# nrf7120E_enga_application register map
Vendor: Nordic Semiconductor; Series: nrf71; File version: 1
CPU: CM33 r0p4, little endian, MPU, FPU, 3 interrupt priority bits, 270 interrupts, 4 SAU regions
Registers are 32-bit, read-write, reset 0x0 unless marked. A register's access mark holds for its fields unless they carry their own. Offsets are from the block's base; [hi:lo] are bit positions; lines under a group give offsets from that group; {n}, {i} and the like mark numbered series; 'fields as' and 'values as' point back to an identical list.

## GLOBAL_TAMPC_S — Tamper controller
Base 0x500EF000
0x100 EVENTS_TAMPER — Tamper controller detected an error.
  [0] EVENTS_TAMPER
    0=NotGenerated (Event not generated); 1=Generated (Event generated)
0x104 EVENTS_WRITEERROR — Attempt to write a VALUE in PROTECT registers without clearing the WRITEPROTECT.
  [0] EVENTS_WRITEERROR
    values as EVENTS_TAMPER.EVENTS_TAMPER
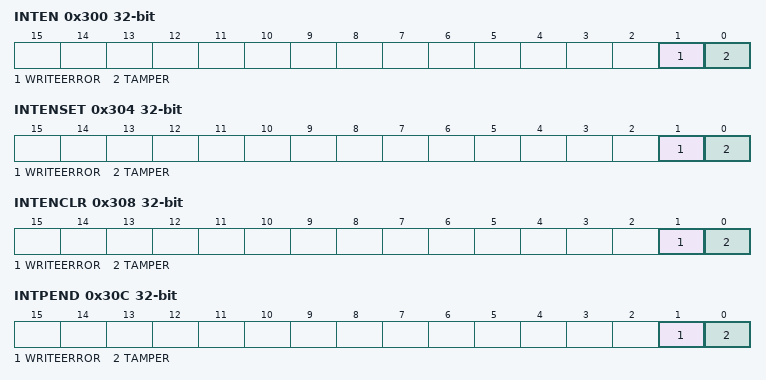
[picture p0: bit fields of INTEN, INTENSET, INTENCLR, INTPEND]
0x300 INTEN — Enable or disable interrupt
  [1] WRITEERROR — Enable or disable interrupt for event WRITEERROR
    0=Disabled; 1=Enabled
  [0] TAMPER — Enable or disable interrupt for event TAMPER
    0=Disabled; 1=Enabled
0x304 INTENSET — Enable interrupt
  [1] WRITEERROR write-1-sets — Write '1' to enable interrupt for event WRITEERROR
    on read: 0=Disabled (Read: Disabled); 1=Enabled (Read: Enabled) | on write: 1=Set (Enable)
  [0] TAMPER write-1-sets — Write '1' to enable interrupt for event TAMPER
    values as WRITEERROR
0x308 INTENCLR — Disable interrupt
  [1] WRITEERROR write-1-clears — Write '1' to disable interrupt for event WRITEERROR
    on read: 0=Disabled (Read: Disabled); 1=Enabled (Read: Enabled) | on write: 1=Clear (Disable)
  [0] TAMPER write-1-clears — Write '1' to disable interrupt for event TAMPER
    values as WRITEERROR
0x30C INTPEND ro — Pending interrupts
  [1] WRITEERROR — Read pending status of interrupt for event WRITEERROR
    on read: 0=NotPending (Read: Not pending); 1=Pending (Read: Pending)
  [0] TAMPER — Read pending status of interrupt for event TAMPER
    values as WRITEERROR
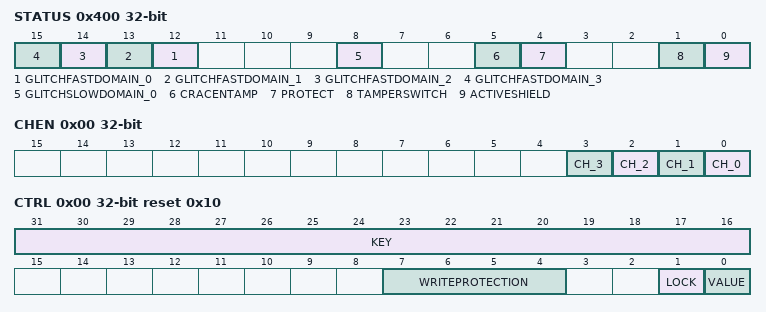
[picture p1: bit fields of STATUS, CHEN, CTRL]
0x400 STATUS write-1-clears — The tamper controller status.
  [all] fields
    0=NotDetected; 1=Detected
  [n+12] GLITCHFASTDOMAIN_{n} (n=0..3) — Fast domain glitch detector {n} detected an error.
  [8] GLITCHSLOWDOMAIN_0 — Slow domain glitch detector 0 detected an error.
  [5] CRACENTAMP — CRACEN detected an error.
  [4] PROTECT — Error detected for the protected signals.
  [1] TAMPERSWITCH — External tamper switch detector detected an error.
  [0] ACTIVESHIELD — Active shield detector detected an error.
0x404 ACTIVESHIELD group — Unspecified
  0x00 CHEN — Active shield detector channel enable register.
    [all] fields
      0=Disabled (Disable channel.); 1=Enabled (Enable channel.)
    [n] CH_{n} (n=0..3) — Enable or disable active shield channel {n}.
0x500 PROTECT group — Unspecified
  {0x0+0x20*j} DOMAIN[{j}] (j=0..0) group — Unspecified
    0x00 DBGEN group — Unspecified
      0x00 CTRL reset 0x10 — Description cluster: Control register for invasive (halting) debug enable for the local debug components within domain n.
        [31:16] KEY wo — Required write key for upper 16 bits. Must be included in all register write operations.
          0x50FA=KEY (Write key value.)
        [7:4] WRITEPROTECTION — The write protection must be cleared to allow updates to the VALUE field.
          0=Disabled (Read: Write protection is disabled.); 1=Enabled (Read: Write protection is enabled.); 15=Clear (Write: Value to clear write protection.)
        [1] LOCK write-once write-1-sets — Lock this register to prevent changes to the VALUE field until next reset.
          0=Disabled (Lock disabled.); 1=Enabled (Lock enabled.)
        [0] VALUE — Set value of dbgen signal.
          0=Low (Signal is logic 0, indicating that invasive debug is disabled.); 1=High (Signal is logic 1, indicating that invasive debug is enabled.)
      0x04 STATUS write-1-clears — Description cluster: Status register for invasive (halting) debug enable for domain n.
        [0] ERROR — Error detection status.
          0=No error detected; 1=Error detected
    0x08 NIDEN group — Unspecified
      0x00 CTRL reset 0x10 — Description cluster: Control register for non-invasive debug enable for the local debug components within domain n.
        [31:16] KEY wo — Required write key for upper 16 bits. Must be included in all register write operations.
          0x50FA=KEY (Write key value.)
        [7:4] WRITEPROTECTION — The write protection must be cleared to allow updates to the VALUE field.
          values as PROTECT.DOMAIN[0].DBGEN.CTRL.WRITEPROTECTION
        [1] LOCK write-once write-1-sets — Lock this register to prevent changes to the VALUE field until next reset.
          0=Disabled (Lock disabled.); 1=Enabled (Lock enabled.)
        [0] VALUE — Set value of niden signal.
          0=Low (Signal is logic 0, indicating that non-invasive debug is disabled.); 1=High (Signal is logic 1, indicating that non-invasive debug is enabled.)
      0x04 STATUS write-1-clears — Description cluster: Status register for non-invasive debug enable for domain n.
        fields as PROTECT.DOMAIN[0].DBGEN.STATUS
    0x10 SPIDEN group — Unspecified
      0x00 CTRL reset 0x10 — Description cluster: Control register for secure priviliged invasive (halting) debug enable for the local debug components within domain n.
        [31:16] KEY wo — Required write key for upper 16 bits. Must be included in all register write operations.
          0x50FA=KEY (Write key value.)
        [7:4] WRITEPROTECTION — The write protection must be cleared to allow updates to the VALUE field.
          values as PROTECT.DOMAIN[0].DBGEN.CTRL.WRITEPROTECTION
        [1] LOCK write-once write-1-sets — Lock this register to prevent changes to the VALUE field until next reset.
          0=Disabled (Lock disabled.); 1=Enabled (Lock enabled.)
        [0] VALUE — Set value of spiden signal.
          0=Low (Signal is logic 0, indicating that secure priviliged invasive debug is disabled.); 1=High (Signal is logic 1, indicating that secure priviliged invasive debug is enabled.)
      0x04 STATUS write-1-clears — Description cluster: Status register for secure priviliged invasive (halting) debug enable for domain n.
        fields as PROTECT.DOMAIN[0].DBGEN.STATUS
    0x18 SPNIDEN group — Unspecified
      0x00 CTRL reset 0x10 — Description cluster: Control register for secure priviliged non-invasive debug enable for the local debug components within domain n.
        [31:16] KEY wo — Required write key for upper 16 bits. Must be included in all register write operations.
          0x50FA=KEY (Write key value.)
        [7:4] WRITEPROTECTION — The write protection must be cleared to allow updates to the VALUE field.
          values as PROTECT.DOMAIN[0].DBGEN.CTRL.WRITEPROTECTION
        [1] LOCK write-once write-1-sets — Lock this register to prevent changes to the VALUE field until next reset.
          0=Disabled (Lock disabled.); 1=Enabled (Lock enabled.)
        [0] VALUE — Set value of spniden signal.
          0=Low (Signal is logic 0, indicating that secure priviliged non-invasive debug is disabled.); 1=High (Signal is logic 1, indicating that secure priviliged non-invasive debug is enabled.)
      0x04 STATUS write-1-clears — Description cluster: Status register for secure priviliged non-invasive debug enable for domain n.
        fields as PROTECT.DOMAIN[0].DBGEN.STATUS
  {0x200+0x10*j} AP[{j}] (j=0..0) group — Unspecified
    0x00 DBGEN group — Unspecified
      0x00 CTRL reset 0x10 — Description cluster: Control register to enable invasive (halting) debug in domain ns access port.
        fields as PROTECT.DOMAIN[0].DBGEN.CTRL
      0x04 STATUS write-1-clears — Description cluster: Status register for invasive (halting) debug enable for domain ns access port.
        fields as PROTECT.DOMAIN[0].DBGEN.STATUS
  0x370 RESETBEHAVIOR group — Unspecified
    0x00 CTRL reset 0x10 — Control register allows for the configuration of reset behavior for specific signals.
      [31:16] KEY wo — Required write key for upper 16 bits. Must be included in all register write operations.
        0x50FA=KEY (Write key value.)
      [7:4] WRITEPROTECTION — The write protection must be cleared to allow updates to the VALUE field.
        values as PROTECT.DOMAIN[0].DBGEN.CTRL.WRITEPROTECTION
      [1] LOCK write-once write-1-sets — Lock this register to prevent changes to the VALUE field until next reset.
        0=Disabled (Lock disabled.); 1=Enabled (Lock enabled.)
      [0] VALUE — Determines the reset behavior for specific signals under certain conditions as defined by the device implementation.
        0=Low (No reset action is triggered for the specified conditions.); 1=High (A reset action is initiated for the specified conditions, resetting the targeted signals to their default state.)
    0x04 STATUS write-1-clears — Status register for the reset control register.
      fields as PROTECT.DOMAIN[0].DBGEN.STATUS
  0x400 ACTIVESHIELD group — Enable active shield detector.
    0x00 CTRL reset 0x10 — Control register for active shield detector enable signal.
      [31:16] KEY wo — Required write key for upper 16 bits. Must be included in all register write operations.
        0x50FA=KEY (Write key value.)
      [7:4] WRITEPROTECTION — The write protection must be cleared to allow updates to the VALUE field.
        values as PROTECT.DOMAIN[0].DBGEN.CTRL.WRITEPROTECTION
      [1] LOCK write-once write-1-sets — Lock this register to prevent changes to the VALUE field until next reset.
        0=Disabled (Lock disabled.); 1=Enabled (Lock enabled.)
      [0] VALUE — Set value of active shield enable signal.
        0=Low (Signal is logic 0.); 1=High (Signal is logic 1.)
    0x04 STATUS write-1-clears — Status register for active shield detector enable signal.
      fields as PROTECT.DOMAIN[0].DBGEN.STATUS
  0x408 TAMPERSWITCH group — Enable tamper switch detector.
    0x00 CTRL reset 0x10 — Control register for external tamper switch enable signal.
      [31:16] KEY wo — Required write key for upper 16 bits. Must be included in all register write operations.
        0x50FA=KEY (Write key value.)
      [7:4] WRITEPROTECTION — The write protection must be cleared to allow updates to the VALUE field.
        values as PROTECT.DOMAIN[0].DBGEN.CTRL.WRITEPROTECTION
      [1] LOCK write-once write-1-sets — Lock this register to prevent changes to the VALUE field until next reset.
        0=Disabled (Lock disabled.); 1=Enabled (Lock enabled.)
      [0] VALUE — Set value of tamper switch enable signal.
        0=Low (Signal is logic 0.); 1=High (Signal is logic 1.)
    0x04 STATUS write-1-clears — Status register for external tamper switch detector enable signal.
      fields as PROTECT.DOMAIN[0].DBGEN.STATUS
  0x438 CRACENTAMP group — Enable tamper detector from CRACEN.
    0x00 CTRL reset 0x11 — Control register for CRACEN tamper detector enable signal.
      [31:16] KEY wo — Required write key for upper 16 bits. Must be included in all register write operations.
        0x50FA=KEY (Write key value.)
      [7:4] WRITEPROTECTION — The write protection must be cleared to allow updates to the VALUE field.
        values as PROTECT.DOMAIN[0].DBGEN.CTRL.WRITEPROTECTION
      [1] LOCK write-once write-1-sets — Lock this register to prevent changes to the VALUE field until next reset.
        0=Disabled (Lock disabled.); 1=Enabled (Lock enabled.)
      [0] VALUE — Set value of CRACEN tamper detector enable signal.
        0=Low (Signal is logic 0.); 1=High (Signal is logic 1.)
    0x04 STATUS write-1-clears — Status register for CRACEN tamper detector enable signal.
      fields as PROTECT.DOMAIN[0].DBGEN.STATUS
  0x440 GLITCHSLOWDOMAIN group — Enable slow domain glitch detectors.
    0x00 CTRL reset 0x11 — Control register for slow domain glitch detectors enable signal.
      [31:16] KEY wo — Required write key for upper 16 bits. Must be included in all register write operations.
        0x50FA=KEY (Write key value.)
      [7:4] WRITEPROTECTION — The write protection must be cleared to allow updates to the VALUE field.
        values as PROTECT.DOMAIN[0].DBGEN.CTRL.WRITEPROTECTION
      [1] LOCK write-once write-1-sets — Lock this register to prevent changes to the VALUE field until next reset.
        0=Disabled (Lock disabled.); 1=Enabled (Lock enabled.)
      [0] VALUE — Set value of slow domain glitch detectors enable signal.
        0=Low (Signal is logic 0.); 1=High (Signal is logic 1.)
    0x04 STATUS write-1-clears — Status register for slow domain glitch detectors enable signal.
      fields as PROTECT.DOMAIN[0].DBGEN.STATUS
  0x448 GLITCHFASTDOMAIN group — Enable fast domain glitch detectors.
    0x00 CTRL reset 0x11 — Control register for fast domain glitch detectors enable signal.
      [31:16] KEY wo — Required write key for upper 16 bits. Must be included in all register write operations.
        0x50FA=KEY (Write key value.)
      [7:4] WRITEPROTECTION — The write protection must be cleared to allow updates to the VALUE field.
        values as PROTECT.DOMAIN[0].DBGEN.CTRL.WRITEPROTECTION
      [1] LOCK write-once write-1-sets — Lock this register to prevent changes to the VALUE field until next reset.
        0=Disabled (Lock disabled.); 1=Enabled (Lock enabled.)
      [0] VALUE — Set value of fast domain glitch detector's enable signal.
        0=Low (Signal is logic 0.); 1=High (Signal is logic 1.)
    0x04 STATUS write-1-clears — Status register for fast domain glitch detectors enable signal.
      fields as PROTECT.DOMAIN[0].DBGEN.STATUS
  0x470 EXTRESETEN group — Trigger a reset when tamper is detected by the external tamper detectors.
    0x00 CTRL reset 0x10 — Control register for external tamper reset enable signal.
      [31:16] KEY wo — Required write key for upper 16 bits. Must be included in all register write operations.
        0x50FA=KEY (Write key value.)
      [7:4] WRITEPROTECTION — The write protection must be cleared to allow updates to the VALUE field.
        values as PROTECT.DOMAIN[0].DBGEN.CTRL.WRITEPROTECTION
      [1] LOCK write-once write-1-sets — Lock this register to prevent changes to the VALUE field until next reset.
        0=Disabled (Lock disabled.); 1=Enabled (Lock enabled.)
      [0] VALUE — Set value of external tamper reset enable signal.
        0=Low (Signal is logic 0.); 1=High (Signal is logic 1.)
    0x04 STATUS write-1-clears — Status register for external tamper reset enable signal.
      fields as PROTECT.DOMAIN[0].DBGEN.STATUS
  0x478 INTRESETEN group — Trigger a reset when tamper is detected by the glitch detectors, signal protector or CRACEN tamper detector.
    0x00 CTRL reset 0x10 — Control register for internal tamper reset enable signal.
      [31:16] KEY wo — Required write key for upper 16 bits. Must be included in all register write operations.
        0x50FA=KEY (Write key value.)
      [7:4] WRITEPROTECTION — The write protection must be cleared to allow updates to the VALUE field.
        values as PROTECT.DOMAIN[0].DBGEN.CTRL.WRITEPROTECTION
      [1] LOCK write-once write-1-sets — Lock this register to prevent changes to the VALUE field until next reset.
        0=Disabled (Lock disabled.); 1=Enabled (Lock enabled.)
      [0] VALUE — Set value of internal tamper reset enable signal.
        0=Low (Signal is logic 0.); 1=High (Signal is logic 1.)
    0x04 STATUS write-1-clears — Status register for internal tamper reset enable signal.
      fields as PROTECT.DOMAIN[0].DBGEN.STATUS
  0x480 ERASEPROTECT group — Device erase protection.
    0x00 CTRL reset 0x10 — Control register for erase protection.
      [31:16] KEY wo — Required write key for upper 16 bits. Must be included in all register write operations.
        0x50FA=KEY (Write key value.)
      [7:4] WRITEPROTECTION — The write protection must be cleared to allow updates to the VALUE field.
        values as PROTECT.DOMAIN[0].DBGEN.CTRL.WRITEPROTECTION
      [1] LOCK write-once write-1-sets — Lock this register to prevent changes to the VALUE field until next reset.
        0=Disabled (Lock disabled.); 1=Enabled (Lock enabled.)
      [0] VALUE — Set value of eraseprotect signal.
        0=Low (Signal is logic 0.); 1=High (Signal is logic 1.)
    0x04 STATUS write-1-clears — Status register for eraseprotect.
      fields as PROTECT.DOMAIN[0].DBGEN.STATUS
